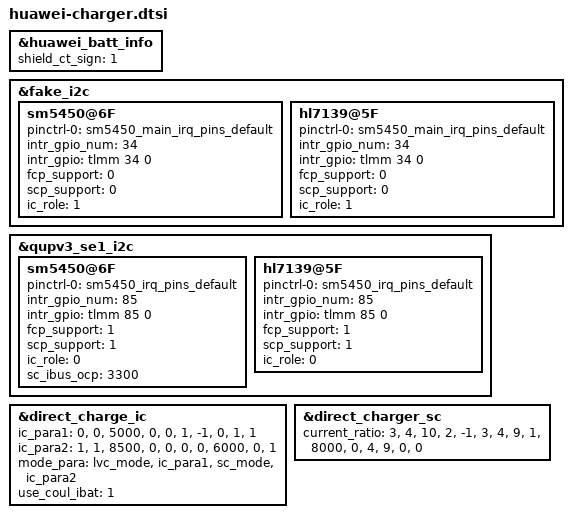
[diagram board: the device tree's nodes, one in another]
&huawei_batt_info {
    shield_ct_sign = <1>;
};

&fake_i2c {
	sm5450@6F{
		pinctrl-0 = <&sm5450_main_irq_pins_default>;
		intr_gpio_num = <34>; /* direct defined GPIO num */
		intr_gpio = <&tlmm 34 0>;
		fcp_support = <0>;
		scp_support = <0>;
		ic_role = <1>;
	};

	hl7139@5F {
		pinctrl-0 = <&sm5450_main_irq_pins_default>;
		intr_gpio_num = <34>; /* direct defined GPIO num */
		intr_gpio = <&tlmm 34 0>;
		fcp_support = <0>;
		scp_support = <0>;
		ic_role = <1>;
	};
};

&qupv3_se1_i2c {
	sm5450@6F{
		pinctrl-0 = <&sm5450_irq_pins_default>;
		intr_gpio_num = <85>; /* direct defined GPIO num */
		intr_gpio = <&tlmm 85 0>;
		fcp_support = <1>;
		scp_support = <1>;
		ic_role = <0>;
	};

	hl7139@5F {
		pinctrl-0 = <&sm5450_irq_pins_default>;
		intr_gpio_num = <85>; /* direct defined GPIO num */
		intr_gpio = <&tlmm 85 0>;
		fcp_support = <1>;
		scp_support = <1>;
		ic_role = <0>;
	};
};

&direct_charge_ic {
	/* ic_index  path_index  max_ibat  ibat_sample_point  vbat_sample_point */
	ic_para1 =
		"0", "0", "5000", "0", "0",
		"1", "-1", "0", "1", "1";
	ic_para2 =
		"1", "1", "8500", "0", "0",
		"0", "0", "6000", "0", "1";
	mode_para =
		"lvc_mode", "ic_para1",
		"sc_mode", "ic_para2";
        use_coul_ibat = <1>;
	status = "ok";
};

&direct_charger_sc {
	current_ratio =
		"3", "4", "10", "2", "-1",
		"3", "4", "9", "1", "8000",
		"0", "4", "9", "0", "0";
};

&qupv3_se1_i2c {
	sm5450@6F {
		sc_ibus_ocp = <3300>;
	};
};
